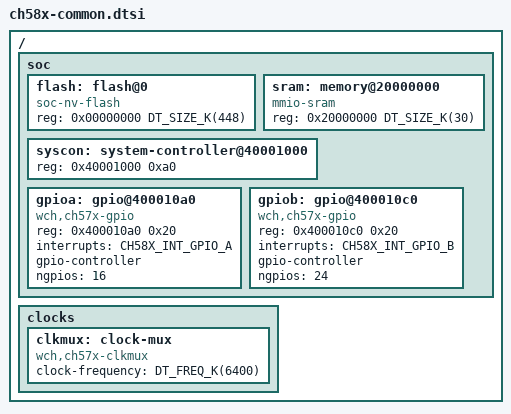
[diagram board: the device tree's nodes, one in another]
/*
 * Copyright (c) 2023 Chen Xingyu <hi@xingrz.me>
 * SPDX-License-Identifier: Apache-2.0
 */

#include <mem.h>
#include <freq.h>

#include <zephyr/dt-bindings/interrupt-controller/ch58x-int.h>

#include <wch/qingke-v4.dtsi>

/ {
	soc {
		flash: flash@0 {
			compatible = "soc-nv-flash";
			reg = <0x00000000 DT_SIZE_K(448)>;
		};

		sram: memory@20000000 {
			compatible = "mmio-sram";
			reg = <0x20000000 DT_SIZE_K(30)>;
		};

		syscon: system-controller@40001000 {
			reg = <0x40001000 0xa0>;
		};

		gpioa: gpio@400010a0 {
			compatible = "wch,ch57x-gpio";
			reg = <0x400010a0 0x20>;
			interrupts = <CH58X_INT_GPIO_A>;
			gpio-controller;
			#gpio-cells = <2>;
			ngpios = <16>;
		};

		gpiob: gpio@400010c0 {
			compatible = "wch,ch57x-gpio";
			reg = <0x400010c0 0x20>;
			interrupts = <CH58X_INT_GPIO_B>;
			gpio-controller;
			#gpio-cells = <2>;
			ngpios = <24>;
		};
	};

	clocks {
		clkmux: clock-mux {
			compatible = "wch,ch57x-clkmux";
			clock-frequency = <DT_FREQ_K(6400)>;
			#clock-cells = <0>;
		};
	};
};
